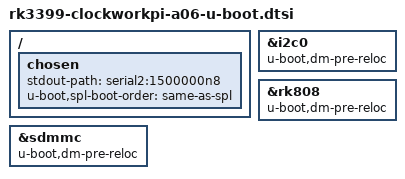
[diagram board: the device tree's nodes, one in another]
// SPDX-License-Identifier: GPL-2.0+

#include "rk3399-u-boot.dtsi"
#include "rk3399-sdram-lpddr4-100.dtsi"

/ {
	chosen {
		stdout-path = "serial2:1500000n8";
		u-boot,spl-boot-order = "same-as-spl", &sdhci, &sdmmc;
	};
};

&i2c0 {
	u-boot,dm-pre-reloc;
};

&rk808 {
	u-boot,dm-pre-reloc;
};

&sdmmc {
	u-boot,dm-pre-reloc;
};
